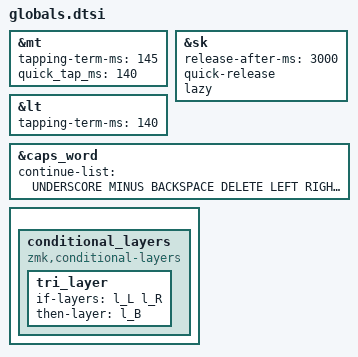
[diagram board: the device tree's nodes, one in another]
&mt {
    tapping-term-ms = <145>;
    quick_tap_ms = <140>;
};

&sk {
    release-after-ms = <3000>;
    quick-release;
    lazy;
};

&lt {
    tapping-term-ms = <140>;
};

&caps_word {
        continue-list = <UNDERSCORE MINUS BACKSPACE DELETE LEFT RIGHT LS(FSLH) FSLH>;
    };

{
    conditional_layers {
    compatible = "zmk,conditional-layers";
    tri_layer {
        if-layers = <l_L l_R>;
        then-layer = <l_B>;
    };
};
}

#define AS(keycode) &as LS(keycode) keycode     // Autoshift Macro

#define de_ae SQT
#define de_s MINUS
#define de_oe SEMI
#define de_ue LBKT
#define de_til RA(RBKT)
#define s_at RA(Q)
#define s_exl LS(N1)
#define s_dol LS(N4)
#define s_eur RA(E)
#define s_ast LS(RBKT)
#define s_sec LS(N3)
#define s_amp LS(N6)
#define s_per LS(N5)
#define s_que LS(MINUS)
#define s_gra EQUAL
